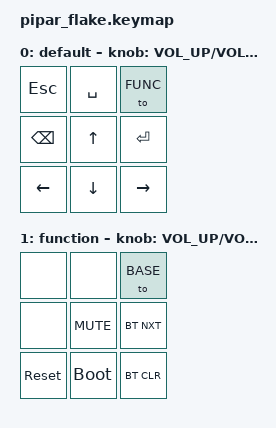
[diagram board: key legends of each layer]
/*
 * Copyright (c) 2022 The ZMK Contributors
 *
 * SPDX-License-Identifier: MIT
 */

#include <behaviors.dtsi>
#include <dt-bindings/zmk/keys.h>
#include <dt-bindings/zmk/bt.h>
#include <dt-bindings/zmk/outputs.h>

#define BASE        0
#define FUNC        1

&encoder_1 {
    status = "okay";
};

/ {
  
  sensors: sensors {
    compatible = "zmk,sensors";
    sensors = <&encoder_1>;
  };

  keymap {
    compatible = "zmk,keymap";

    default_layer {
        // ---------------------------//
        // | ESC  | SPACE | Layer 2 | //
        // | BSPC | UP    |  ENTER  | //
        // | LEFT | DOWN  | RIGHT   | //
        display-name = "default";
        bindings = <
            &kp ESC  &kp SPACE  &to FUNC
            &kp BSPC &kp UP     &kp ENTER
            &kp LEFT &kp DOWN   &kp RIGHT
        >;

      sensor-bindings = <&inc_dec_kp C_VOLUME_UP C_VOLUME_DOWN>;
    };

    function_layer {
        // --------------------------- //
        // | none | none | Layer 2 |   //
        // | none | MUTE |  bt_nxt   |   //
        // | reset | boot | bt_clr |   //
        display-name = "function";
        bindings = <
        &none       &none       &to BASE
        &none       &kp C_MUTE  &bt BT_NXT
        &sys_reset  &bootloader &bt BT_CLR
        >;

      sensor-bindings = <&inc_dec_kp C_VOLUME_UP C_VOLUME_DOWN>;
    };
  };
};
